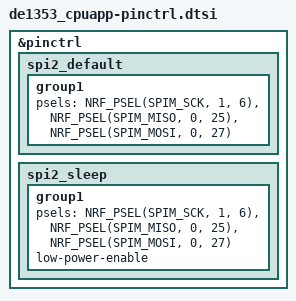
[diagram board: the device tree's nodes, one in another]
/*
 * Copyright (c) 2022 Nordic Semiconductor
 * SPDX-License-Identifier: Apache-2.0
 */

&pinctrl {
	spi2_default: spi2_default {
		group1 {
			psels = <NRF_PSEL(SPIM_SCK, 1, 6)>,
				<NRF_PSEL(SPIM_MISO, 0, 25)>,
				<NRF_PSEL(SPIM_MOSI, 0, 27)>;
		};
	};

	spi2_sleep: spi2_sleep {
		group1 {
			psels = <NRF_PSEL(SPIM_SCK, 1, 6)>,
				<NRF_PSEL(SPIM_MISO, 0, 25)>,
				<NRF_PSEL(SPIM_MOSI, 0, 27)>;
			low-power-enable;
		};
	};

};
